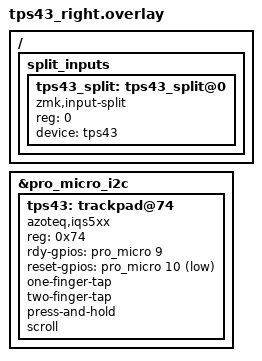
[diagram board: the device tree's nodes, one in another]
#include <zephyr/dt-bindings/gpio/gpio.h>

&pro_micro_i2c {
    status = "okay";

    tps43: trackpad@74 {
        compatible = "azoteq,iqs5xx";
        reg = <0x74>;
        status = "okay";

        /* Provisional wiring: RDY -> D9, NRST -> D10. D8 is a key-matrix pin. */
        rdy-gpios = <&pro_micro 9 GPIO_ACTIVE_HIGH>;
        reset-gpios = <&pro_micro 10 GPIO_ACTIVE_LOW>;

        one-finger-tap;
        two-finger-tap;
        press-and-hold;
        scroll;
    };
};

/ {
    split_inputs {
        #address-cells = <1>;
        #size-cells = <0>;

        tps43_split: tps43_split@0 {
            compatible = "zmk,input-split";
            reg = <0>;
            device = <&tps43>;
        };
    };
};
